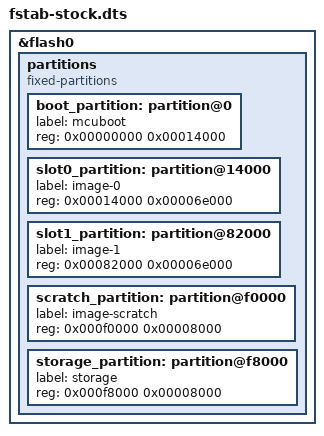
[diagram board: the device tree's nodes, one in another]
/*
 * Copyright (c) 2019 Nordic Semiconductor ASA
 *
 * SPDX-License-Identifier: Apache-2.0
 */

/* Flash partition table compatible with Nordic nRF5 bootloader */

&flash0 {
	partitions {
		compatible = "fixed-partitions";
		#address-cells = <1>;
		#size-cells = <1>;

		/* MCUboot placed after Nordic MBR.
		 * The size of this partition ensures that MCUBoot
		 * can be built with CDC ACM support and w/o optimizations.
		 */
		boot_partition: partition@0 {
			label = "mcuboot";
			reg = <0x00000000 0x00014000>;
		};

		slot0_partition: partition@14000 {
			label = "image-0";
			reg = <0x00014000 0x00006e000>;
		};
		slot1_partition: partition@82000 {
			label = "image-1";
			reg = <0x00082000 0x00006e000>;
		};

		scratch_partition: partition@f0000 {
			label = "image-scratch";
			reg = <0x000f0000 0x00008000>;
		};

		/*
		 * The flash starting at 0x000f8000 and ending at
		 * 0x000fffff is reserved for use by the application.
		 */

		/* Storage partition will be used by FCB/NFFS/NVS if enabled. */
		storage_partition: partition@f8000 {
			label = "storage";
			reg = <0x000f8000 0x00008000>;
		};
	};
};
